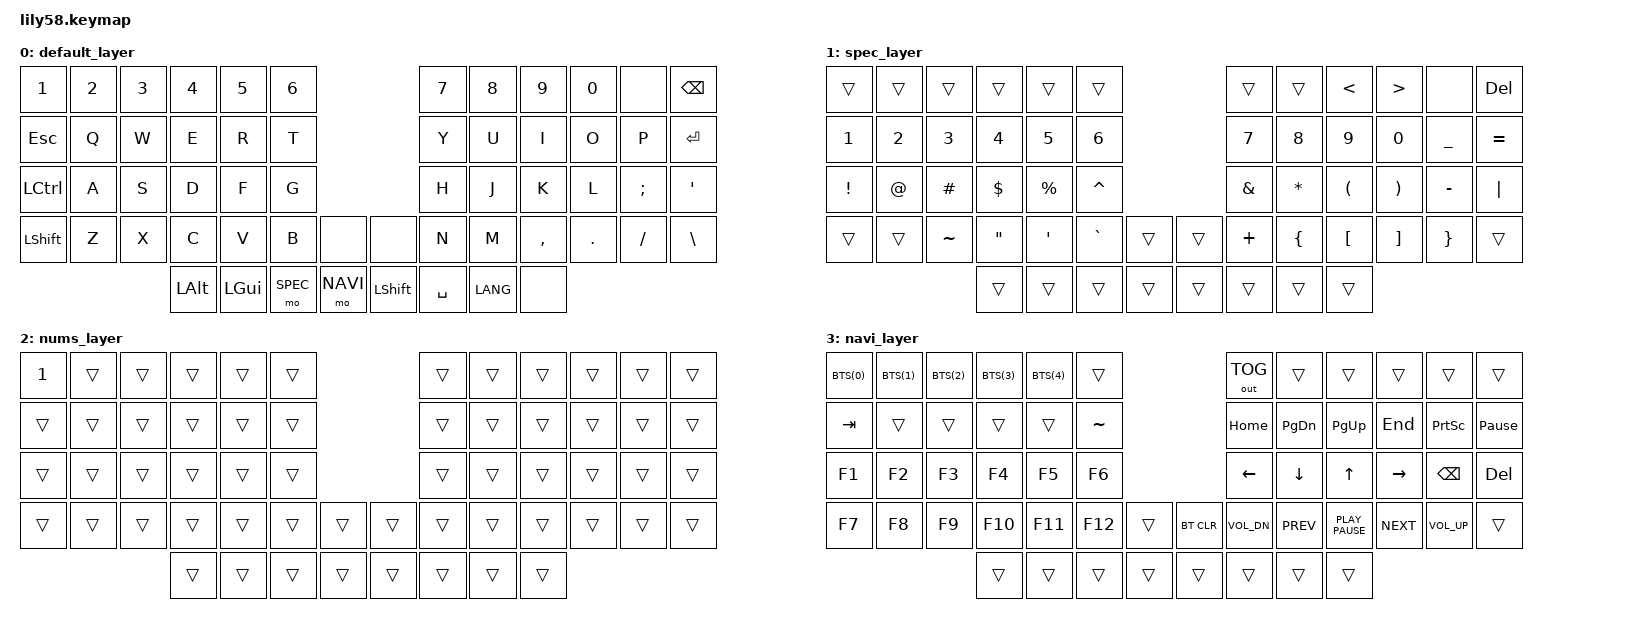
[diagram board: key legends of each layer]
/*
 * Copyright (c) 2020 The ZMK Contributors
 *
 * SPDX-License-Identifier: MIT
 */

#include <behaviors.dtsi>
#include <dt-bindings/zmk/keys.h>
#include <dt-bindings/zmk/bt.h>
#include <dt-bindings/zmk/outputs.h>
#include <dt-bindings/zmk/ext_power.h>

#define SPEC 1
#define NUMS 2
#define NAVI 3
#define LANG LC(SPACE)
#define BTS(n) &bt BT_SEL n

/ {
	keymap {
		compatible = "zmk,keymap";

		default_layer {
// ---------------------------------------------------------------------------------------------------------
// |   1    |  2  |  3  |  4  |  5  |   6   |                    |   7   |   8   |  9  |  0  |     | BKSPC |
// |  ESC   |  Q  |  W  |  E  |  R  |   T   |                    |   Y   |   U   |  I  |  O  |  P  | ENTER |
// |  CTRL  |  A  |  S  |  D  |  F  |   G   |                    |   H   |   J   |  K  |  L  |  ;  |   '   |
// |  SHIFT |  Z  |  X  |  C  |  V  |   B   |        |  |        |   N   |   M   |  ,  |  .  |  /  |   \   |
//                      | ALT | GUI | SPEC  |  NAVI  |  | SHIFT  |  SPC  | LANG  |     |
			bindings = <
&kp N1    &kp N2 &kp N3 &kp N4   &kp N5   &kp N6                         &kp N7 &kp N8   &kp N9    &kp N0  &none     &kp BSPC
&kp ESC   &kp Q  &kp W  &kp E    &kp R    &kp T                          &kp Y  &kp U    &kp I     &kp O   &kp P     &kp ENTER
&kp LCTRL &kp A  &kp S  &kp D    &kp F    &kp G                          &kp H  &kp J    &kp K     &kp L   &kp SEMI  &kp SQT
&kp LSHFT &kp Z  &kp X  &kp C    &kp V    &kp B    &none      &none      &kp N  &kp M    &kp COMMA &kp DOT &kp SLASH &kp BACKSLASH
                        &kp LALT &kp LGUI &mo SPEC &mo NAVI   &kp LSHFT  &kp SPACE  &kp LANG  &none
			>;
		};

		spec_layer {
// ----------------------------------------------------------------------------------------------------
// |     |     |     |     |     |       |                    |       |       |  <  |  >  |     | DEL |
// |  1  |  2  |  3  |  4  |  5  |   6   |                    |   7   |   8   |  9  |  0  |  _  |  =  |
// |  !  |  @  |  #  |  $  |  %  |   ^   |                    |   &   |   *   |  (  |  )  |  -  |  |  |
// |     |     |  ~  |  "  |  '  |   `   |        |  |        |   +   |   {   |  [  |  ]  |  }  |     |
//                   |     |     |       |        |  |        |       |       |     |
			bindings = <
&trans    &trans  &trans     &trans     &trans    &trans                        &trans    &trans     &kp LT    &kp GT    &none      &kp DEL
&kp N1    &kp N2  &kp N3     &kp N4     &kp N5    &kp N6                        &kp N7    &kp N8     &kp N9    &kp N0    &kp UNDER  &kp EQUAL
&kp EXCL  &kp AT  &kp HASH   &kp DOLLAR &kp PRCNT &kp CARET                     &kp AMPS  &kp ASTRK  &kp LPAR  &kp RPAR  &kp MINUS  &kp PIPE
&trans    &trans  &kp TILDE  &kp DQT    &kp SQT   &kp GRAVE   &trans  &trans    &kp PLUS  &kp LBRC   &kp LBKT  &kp RBKT  &kp RBRC   &trans
                             &trans     &trans    &trans      &trans  &trans    &trans    &trans   &trans
			>;
		};

		nums_layer {
// ----------------------------------------------------------------------------------------------------
// |     |     |     |     |     |       |                    |       |       |     |     |     |     |
// |     |     |     |     |     |       |                    |       |       |     |     |     |     |
// |     |     |     |     |     |       |                    |       |       |     |     |     |     |
// |     |     |     |     |     |       |        |  |        |       |       |     |     |     |     |
//                   |     |     |       |        |  |        |       |       |     |
			bindings = <
&kp N1 &trans &trans &trans   &trans   &trans                       &trans     &trans   &trans     &trans  &trans    &trans
&trans &trans &trans &trans   &trans   &trans                       &trans     &trans   &trans     &trans  &trans    &trans
&trans &trans &trans &trans   &trans   &trans                       &trans     &trans   &trans     &trans  &trans    &trans
&trans &trans &trans &trans   &trans   &trans   &trans    &trans    &trans     &trans   &trans     &trans  &trans    &trans
                     &trans   &trans   &trans   &trans    &trans    &trans     &trans   &trans
			>;
		};

		navi_layer {
// ----------------------------------------------------------------------------------------------------
// | BT1 | BT1 | BT1 | BT1 |     |       |                    | OUT_T |       |      |     |     |     |
// | TAB |     |     |     |     |   ё   |                    | HOME  | PGDN  | PGUP | END | PSCR|PAUSE|
// | F1  |     |     |     |     |       |                    | LEFT  | DOWN  |  UP  |RIGHT|BKSPC| DEL |
// |     |     |     |     |     |  F12  |        |  | BT CLR | VOLDN | PREV  |  PP  | NEXT|VOLUP|     |
//                   |     |     |       |        |  |        |       |       |      |
			bindings = <
BTS(0)  BTS(1) BTS(2) BTS(3)   BTS(4)   &trans                       &out OUT_TOG  &trans     &trans           &trans     &trans        &trans
&kp TAB &trans &trans &trans   &trans   &kp TILDE                    &kp HOME      &kp PG_DN  &kp PG_UP        &kp END    &kp PSCRN     &kp PAUSE_BREAK
&kp F1  &kp F2 &kp F3 &kp F4   &kp F5   &kp F6                       &kp LEFT      &kp DOWN   &kp UP           &kp RIGHT  &kp BSPC      &kp DEL
&kp F7  &kp F8 &kp F9 &kp F10  &kp F11  &kp F12  &trans   &bt BT_CLR &kp C_VOL_DN  &kp K_PREV &kp K_PLAY_PAUSE &kp K_NEXT &kp C_VOL_UP  &trans
                      &trans   &trans   &trans   &trans   &trans     &trans        &trans     &trans
			>;
		};
  };
};
